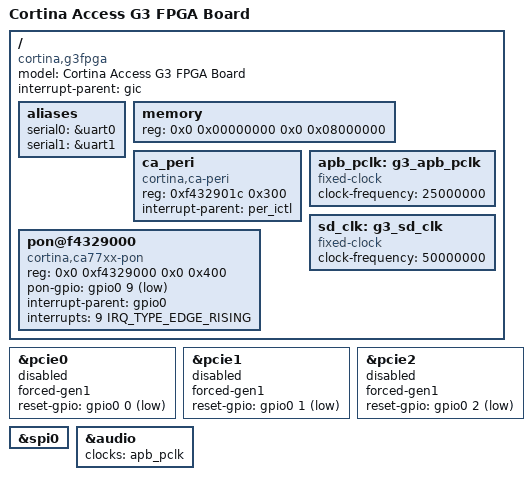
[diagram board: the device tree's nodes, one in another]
/*
 * dts file for Cortina Access G3 FPGA Development Board
 *
 * Copyright (C) 2015, Cortina Access
 *
 */

/dts-v1/;

/memreserve/ 0x0EC00000 0x01400000;

#include <dt-bindings/gpio/gpio.h>
#include "ca7774-soc_fpga.dtsi"
#include "ca77xx-nand.dtsi"
#include "ca77xx-crypto.dtsi"

/* /memreserve/ 0x00000000 0x07400000; */

/* board specific and SoC overrides below */
/ {
	model = "Cortina Access G3 FPGA Board";
	compatible = "cortina,g3fpga";
	#address-cells = <2>;
	#size-cells = <2>;
	interrupt-parent = <&gic>;

	aliases {
		serial0 = &uart0;
		serial1 = &uart1;
	};

	memory { /* 128MB */
		device_type = "memory";
		reg = <0x0 0x00000000 0x0 0x08000000>;
	};

	ca_peri{
		compatible = "cortina,ca-peri";
		reg = <0xf432901c  0x300>;
		interrupt-parent = <&per_ictl>;
	};
	
	/* APB clock varies based on G3 config */
	/* TODO: develop clock driver to switch between freq. for now use fixed freq. */
	apb_pclk: g3_apb_pclk {
		compatible = "fixed-clock";
		#clock-cells = <0>;
		clock-frequency = <25000000>;
	};

	sd_clk: g3_sd_clk {
		compatible = "fixed-clock";
		#clock-cells = <0>;
		clock-frequency = <50000000>;
	};

#if 0
	/* SD clock provides 50/100/200 Mhz */
	/* TODO: develop clock driver to switch between this freq. for now use fixed freq. */
	sd_clk: g3_sd_clk {
		compatible = "fixed-clock";
		#clock-cells = <0>;
		clock-frequency = <50000000>;
	};
	/* PCIe clock provides 250 Mhz */
	pcie_clk: g3_pcie_clk {
		compatible = "fixed-clock";
		#clock-cells = <0>;
		clock-frequency = <250000000>;
	};
	/* PCIe BUS clock provides 250 Mhz */
	pcie_bclk: g3_pcie_bclk {
		compatible = "fixed-clock";
		#clock-cells = <0>;
		clock-frequency = <250000000>;
	};

	/* USB 2 clock provides 60 Mhz */
	usb2_clk: g3_usb2_clk {
		compatible = "fixed-clock";
		#clock-cells = <0>;
		clock-frequency = <60000000>;
	};

	smb { /* simple bus */

		uart0: uart@0xf4570114 {
			device_type = "serial";
			compatible = "cortina,serial";
			reg = <0x0 0xf4570114 0x0 0x30>; /* TODO - when memory map available */
			clocks = <&apb_pclk>;
			clock-names = "apb_pclk";
			interrupts = <0 32 0x1>; /* TODO - when interrupt map available */
		};

		uart1: uart@f4570144 {
			device_type = "serial";
			compatible = "cortina,serial";
			reg = <0x0 0xf4570144 0x0 0x30>; /* TODO - when memory map available */
			clocks = <&apb_pclk>;
			interrupts = <0 32 0x1>; /* edge triggered */
		};

	};
#endif

	pon@f4329000 {
		compatible = "cortina,ca77xx-pon";
		reg = <0x0 0xf4329000  0x0 0x400>;
		pon-gpio = <&gpio0 9 GPIO_ACTIVE_LOW>;
		interrupt-parent = <&gpio0>;
		interrupts = <9 IRQ_TYPE_EDGE_RISING>;
	};
};

/* "okay" - turn on, "disabled" - turn off */
&pcie0 {
	status = "disabled";
	forced-gen1;
	reset-gpio = <&gpio0 0 GPIO_ACTIVE_LOW>;
};

&pcie1 {
	status = "disabled";
	forced-gen1;
	reset-gpio = <&gpio0 1 GPIO_ACTIVE_LOW>;
};

&pcie2 {
	status = "disabled";
	forced-gen1;
	reset-gpio = <&gpio0 2 GPIO_ACTIVE_LOW>;
};

&spi0 {
	/* explained here proslic_api/docs/ProSLIC_API_QuickStart_Linux.pdf */
#if 0
	/* Si32183: channel_count = 1, with isi, mode spi-cpha
	   Si32285: channel_count = 2, with isi, mode spi-cpha
	 */
	proslic_spi0: proslic_spi0@0 {
		compatible = "silabs,proslic_spi", "rohm,dh2228fv";
		status = "okay";
		spi-max-frequency = <2500000>;
		isi;
		reg = <0>;
		spi-cpha;
		channel_count = <2>;
		debug_level = <7>;
		reset-gpio = <&gpio0 3 GPIO_ACTIVE_LOW>;
	};
#endif

#if 0
	/* Si32287: channel_count = 1, w/o isi, mode spi-cpha/spi-cpol */
	proslic_spi0: proslic_spi0@0 {
		compatible = "silabs,proslic_spi", "rohm,dh2228fv";
		status = "okay";
		spi-max-frequency = <2500000>;
		reg = <0>;
		spi-cpha;
		spi-cpol;
		channel_count = <2>;
		debug_level = <7>;
		reset-gpio = <&gpio0 3 GPIO_ACTIVE_LOW>;
	};
#endif
};

&audio {
	clocks = <&apb_pclk>;
};
